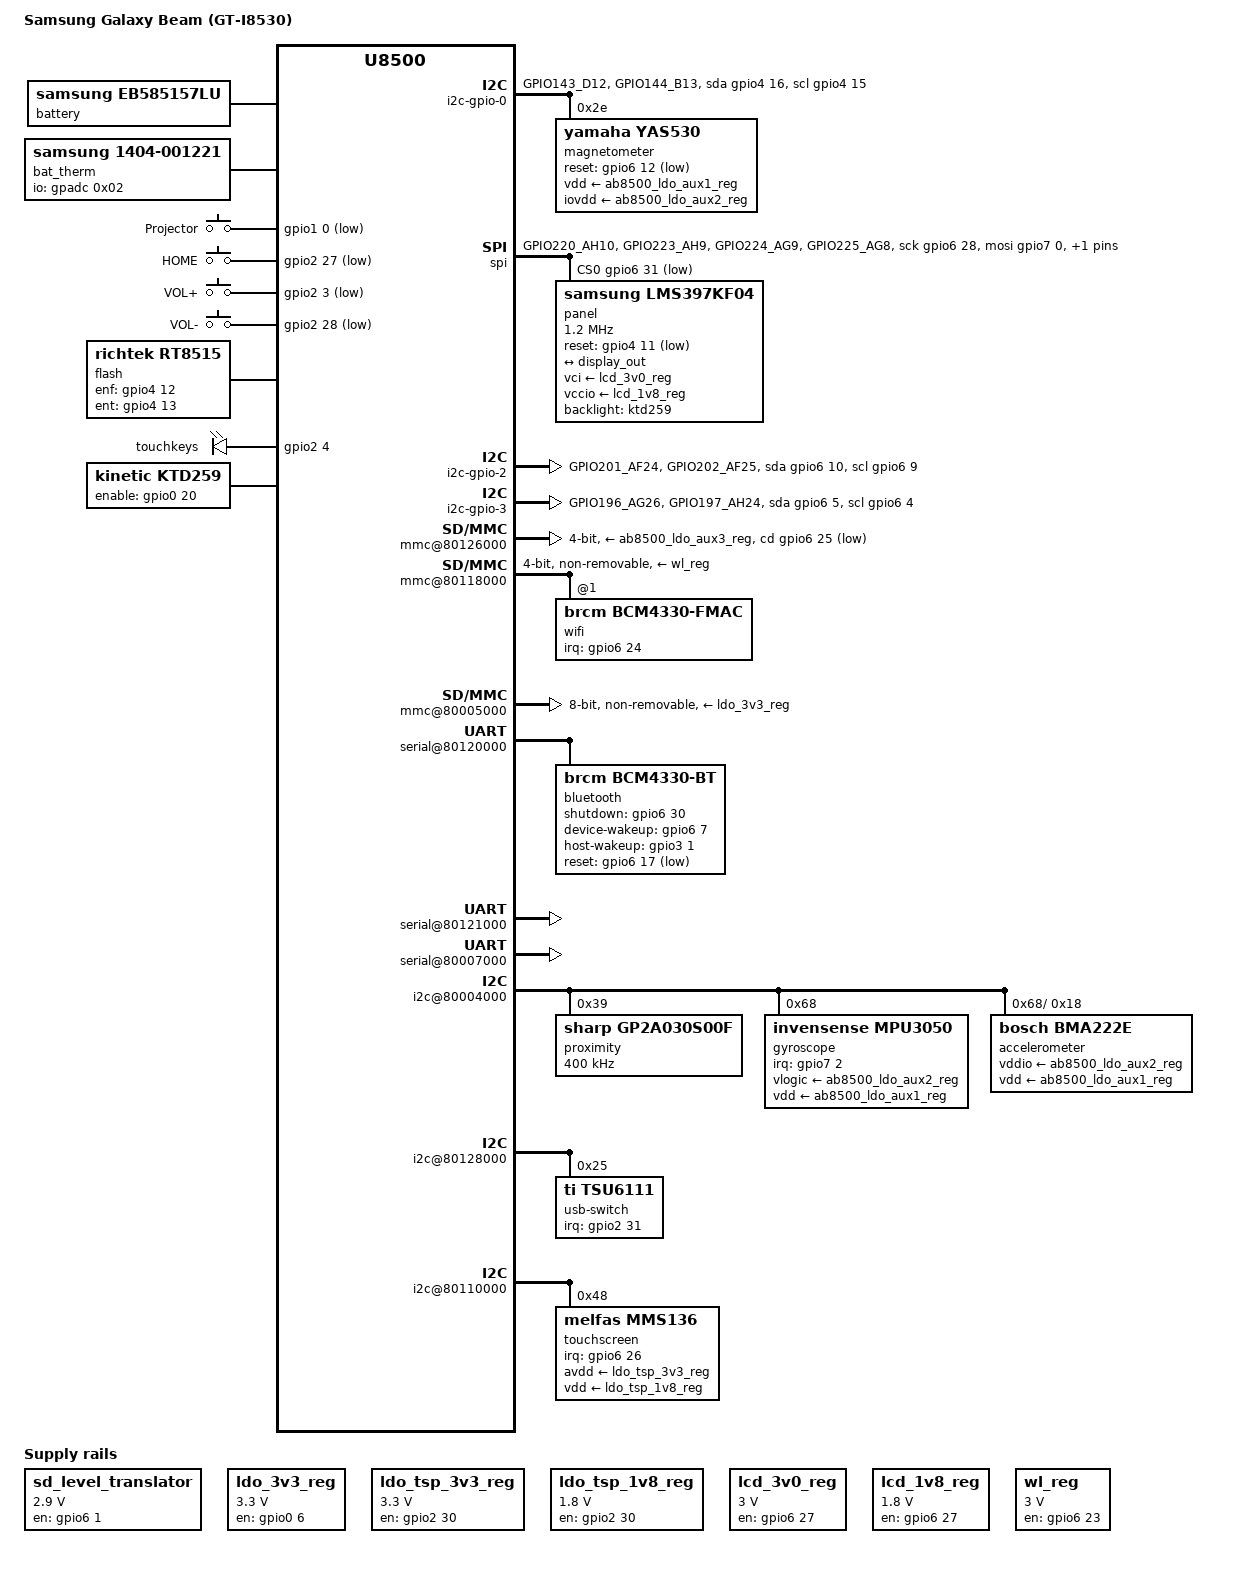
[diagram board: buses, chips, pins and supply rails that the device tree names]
/dts-v1/;
#include "ste-db8500.dtsi"
#include "ste-ab8500.dtsi"
#include "ste-dbx5x0-pinctrl.dtsi"
#include <dt-bindings/gpio/gpio.h>
#include <dt-bindings/leds/common.h>
#include <dt-bindings/input/input.h>
#include <dt-bindings/interrupt-controller/irq.h>
/ {
	model = "Samsung Galaxy Beam (GT-I8530)";
	compatible = "samsung,gavini", "st-ericsson,u8500";
	chosen {
		stdout-path = &serial2;
	};
	battery: battery {
		compatible = "samsung,eb585157lu";
	};
	thermal-zones {
		battery-thermal {
			polling-delay = <0>;
			polling-delay-passive = <0>;
			thermal-sensors = <&bat_therm>;
			trips {
				battery-crit-hi {
					temperature = <70000>;
					hysteresis = <2000>;
					type = "critical";
				};
			};
		};
	};
	bat_therm: thermistor {
		compatible = "samsung,1404-001221";
		io-channels = <&gpadc 0x02>;  
		pullup-uv = <1800000>;
		pullup-ohm = <230000>;
		pulldown-ohm = <0>;
		#thermal-sensor-cells = <0>;
	};
	sd_level_translator: regulator-gpio {
		compatible = "regulator-fixed";
		gpios = <&gpio6 1 GPIO_ACTIVE_HIGH>;
		enable-active-high;
		regulator-name = "sd-level-translator";
		regulator-min-microvolt = <2900000>;
		regulator-max-microvolt = <2900000>;
		regulator-type = "voltage";
		startup-delay-us = <200>;
		pinctrl-names = "default";
		pinctrl-0 = <&sd_level_translator_default>;
	};
	ldo_3v3_reg: regulator-gpio-ldo-3v3 {
		compatible = "regulator-fixed";
		regulator-name = "VMEM_3V3";
		regulator-min-microvolt = <3300000>;
		regulator-max-microvolt = <3300000>;
		gpio = <&gpio0 6 GPIO_ACTIVE_HIGH>;
		startup-delay-us = <5000>;  
		enable-active-high;
		pinctrl-names = "default";
		pinctrl-0 = <&emmc_ldo_en_default_mode>;
	};
	ldo_tsp_3v3_reg: regulator-gpio-tsp-ldo-3v3 {
		compatible = "regulator-fixed";
		regulator-name = "LDO_TSP_A3V3";
		regulator-min-microvolt = <3300000>;
		regulator-max-microvolt = <3300000>;
		gpio = <&gpio2 30 GPIO_ACTIVE_HIGH>;
		startup-delay-us = <70000>;
		enable-active-high;
		pinctrl-names = "default";
		pinctrl-0 = <&tsp_ldo_en_default_mode>;
	};
	ldo_tsp_1v8_reg: regulator-gpio-tsp-ldo-1v8 {
		compatible = "regulator-fixed";
		regulator-name = "VREG_TSP_1V8";
		regulator-min-microvolt = <1800000>;
		regulator-max-microvolt = <1800000>;
		gpio = <&gpio2 30 GPIO_ACTIVE_HIGH>;
		startup-delay-us = <70000>;
		enable-active-high;
		pinctrl-names = "default";
		pinctrl-0 = <&tsp_ldo_en_default_mode>;
	};
	lcd_3v0_reg: regulator-gpio-lcd-3v0 {
		compatible = "regulator-fixed";
		regulator-name = "VREG_LCD_3V0";
		regulator-min-microvolt = <3000000>;
		regulator-max-microvolt = <3000000>;
		gpio = <&gpio6 27 GPIO_ACTIVE_HIGH>;
		enable-active-high;
		pinctrl-names = "default";
		pinctrl-0 = <&lcd_pwr_en_default_mode>;
	};
	lcd_1v8_reg: regulator-gpio-lcd-1v8 {
		compatible = "regulator-fixed";
		regulator-name = "VREG_LCD_1V8";
		regulator-min-microvolt = <1800000>;
		regulator-max-microvolt = <1800000>;
		gpio = <&gpio6 27 GPIO_ACTIVE_HIGH>;
		enable-active-high;
		pinctrl-names = "default";
		pinctrl-0 = <&lcd_pwr_en_default_mode>;
	};
	wl_reg: regulator-gpio-wlan {
		compatible = "regulator-fixed";
		regulator-name = "WL_REG_ON";
		regulator-min-microvolt = <3000000>;
		regulator-max-microvolt = <3000000>;
		startup-delay-us = <100000>;
		gpio = <&gpio6 23 GPIO_ACTIVE_HIGH>;
		enable-active-high;
		pinctrl-names = "default";
		pinctrl-0 = <&wlan_ldo_en_default>;
	};
	gpio-keys {
		compatible = "gpio-keys";
		pinctrl-names = "default";
		pinctrl-0 = <&gpio_keys_default_mode>;
		button-projector {
			linux,code = <KEY_SWITCHVIDEOMODE>;
			label = "Projector";
			gpios = <&gpio1 0 GPIO_ACTIVE_LOW>;
		};
		button-home {
			linux,code = <KEY_HOME>;
			label = "HOME";
			gpios = <&gpio2 27 GPIO_ACTIVE_LOW>;
		};
		button-volup {
			linux,code = <KEY_VOLUMEUP>;
			label = "VOL+";
			gpios = <&gpio2 3 GPIO_ACTIVE_LOW>;
		};
		button-voldown {
			linux,code = <KEY_VOLUMEDOWN>;
			label = "VOL-";
			gpios = <&gpio2 28 GPIO_ACTIVE_LOW>;
		};
	};
	flash {
		compatible = "richtek,rt8515";
		enf-gpios = <&gpio4 12 GPIO_ACTIVE_HIGH>;
		ent-gpios = <&gpio4 13 GPIO_ACTIVE_HIGH>;
		richtek,rfs-ohms = <16000>;
		richtek,rts-ohms = <100000>;
		pinctrl-names = "default";
		pinctrl-0 = <&gpio_flash_default_mode>;
		led {
			function = LED_FUNCTION_FLASH;
			color = <LED_COLOR_ID_WHITE>;
			flash-max-timeout-us = <250000>;
			flash-max-microamp = <343750>;
			led-max-microamp = <55000>;
		};
	};
	gpio-leds {
		compatible = "gpio-leds";
		pinctrl-names = "default";
		pinctrl-0 = <&gpio_leds_default_mode>;
		used-led {
			label = "touchkeys";
			gpios = <&gpio2 4 GPIO_ACTIVE_HIGH>;
			default-state = "on";
		};
	};
	ktd259: backlight {
		compatible = "kinetic,ktd259";
		enable-gpios = <&gpio0 20 GPIO_ACTIVE_HIGH>;
		default-brightness = <13>;
		pinctrl-names = "default";
		pinctrl-0 = <&ktd259_backlight_default_mode>;
	};
	i2c-gpio-0 {
		compatible = "i2c-gpio";
		sda-gpios = <&gpio4 16 (GPIO_ACTIVE_HIGH|GPIO_OPEN_DRAIN)>;
		scl-gpios = <&gpio4 15 (GPIO_ACTIVE_HIGH|GPIO_OPEN_DRAIN)>;
		pinctrl-names = "default";
		pinctrl-0 = <&i2c_gpio_0_default>;
		#address-cells = <1>;
		#size-cells = <0>;
		magnetometer@2e {
			compatible = "yamaha,yas530";
			reg = <0x2e>;
			vdd-supply = <&ab8500_ldo_aux1_reg>;
			iovdd-supply = <&ab8500_ldo_aux2_reg>;
			reset-gpios = <&gpio6 12 GPIO_ACTIVE_LOW>;
			pinctrl-names = "default";
			pinctrl-0 = <&yas530_default>;
		};
	};
	spi {
		compatible = "spi-gpio";
		sck-gpios = <&gpio6 28 GPIO_ACTIVE_HIGH>;
		mosi-gpios = <&gpio7 0 GPIO_ACTIVE_HIGH>;
		miso-gpios = <&gpio7 1 GPIO_ACTIVE_HIGH>;
		cs-gpios = <&gpio6 31 GPIO_ACTIVE_LOW>;
		num-chipselects = <1>;
		pinctrl-names = "default";
		pinctrl-0 = <&spi_gpio_0_default>;
		#address-cells = <1>;
		#size-cells = <0>;
		panel@0 {
			compatible = "samsung,lms397kf04";
			spi-max-frequency = <1200000>;
			spi-cpha;
			spi-cpol;
			reg = <0>;
			vci-supply = <&lcd_3v0_reg>;
			vccio-supply = <&lcd_1v8_reg>;
			reset-gpios = <&gpio4 11 GPIO_ACTIVE_LOW>;
			pinctrl-names = "default";
			pinctrl-0 = <&panel_default_mode>;
			backlight = <&ktd259>;
			port {
				panel_in: endpoint {
					remote-endpoint = <&display_out>;
				};
			};
		};
	};
	i2c-gpio-2 {
		compatible = "i2c-gpio";
		sda-gpios = <&gpio6 10 (GPIO_ACTIVE_HIGH|GPIO_OPEN_DRAIN)>;
		scl-gpios = <&gpio6 9 (GPIO_ACTIVE_HIGH|GPIO_OPEN_DRAIN)>;
		pinctrl-names = "default";
		pinctrl-0 = <&i2c_gpio_2_default>;
		#address-cells = <1>;
		#size-cells = <0>;
	};
	i2c-gpio-3 {
		compatible = "i2c-gpio";
		sda-gpios = <&gpio6 5 (GPIO_ACTIVE_HIGH|GPIO_OPEN_DRAIN)>;
		scl-gpios = <&gpio6 4 (GPIO_ACTIVE_HIGH|GPIO_OPEN_DRAIN)>;
		pinctrl-names = "default";
		pinctrl-0 = <&i2c_gpio_3_default>;
		#address-cells = <1>;
		#size-cells = <0>;
	};
	soc {
		mmc@80126000 {
			arm,primecell-periphid = <0x10480180>;
			max-frequency = <50000000>;
			bus-width = <4>;
			cap-sd-highspeed;
			cap-mmc-highspeed;
			st,sig-pin-fbclk;
			full-pwr-cycle;
			vmmc-supply = <&ab8500_ldo_aux3_reg>;
			vqmmc-supply = <&sd_level_translator>;
			pinctrl-names = "default", "sleep";
			pinctrl-0 = <&mc0_a_2_default>;
			pinctrl-1 = <&mc0_a_2_sleep>;
			cd-gpios  = <&gpio6 25 GPIO_ACTIVE_LOW>;
			status = "okay";
		};
		mmc@80118000 {
			arm,primecell-periphid = <0x10480180>;
			max-frequency = <50000000>;
			bus-width = <4>;
			non-removable;
			cap-sd-highspeed;
			pinctrl-names = "default", "sleep";
			pinctrl-0 = <&mc1_a_2_default>;
			pinctrl-1 = <&mc1_a_2_sleep>;
			vmmc-supply = <&wl_reg>;
			#address-cells = <1>;
			#size-cells = <0>;
			status = "okay";
			wifi@1 {
				compatible = "brcm,bcm4330-fmac", "brcm,bcm4329-fmac";
				reg = <1>;
				interrupt-parent = <&gpio6>;
				interrupts = <24 IRQ_TYPE_EDGE_FALLING>;
				interrupt-names = "host-wake";
				pinctrl-names = "default";
				pinctrl-0 = <&wlan_default_mode>;
			};
		};
		mmc@80005000 {
			arm,primecell-periphid = <0x10480180>;
		        max-frequency = <50000000>;
			bus-width = <8>;
			non-removable;
			cap-mmc-highspeed;
			mmc-ddr-1_8v;
			no-sdio;
			no-sd;
			vmmc-supply = <&ldo_3v3_reg>;
			pinctrl-names = "default", "sleep";
			pinctrl-0 = <&mc2_a_1_default>;
			pinctrl-1 = <&mc2_a_1_sleep>;
			status = "okay";
		};
		serial@80120000 {
			pinctrl-names = "default", "sleep";
			pinctrl-0 = <&u0_a_1_default>;
			pinctrl-1 = <&u0_a_1_sleep>;
			status = "okay";
			bluetooth {
				compatible = "brcm,bcm4330-bt";
				shutdown-gpios = <&gpio6 30 GPIO_ACTIVE_HIGH>;
				device-wakeup-gpios = <&gpio6 7 GPIO_ACTIVE_HIGH>;
				host-wakeup-gpios = <&gpio3 1 GPIO_ACTIVE_HIGH>;
				reset-gpios = <&gpio6 17 GPIO_ACTIVE_LOW>;
				pinctrl-names = "default";
				pinctrl-0 = <&bluetooth_default_mode>;
			};
		};
		serial@80121000 {
			status = "okay";
			pinctrl-names = "default", "sleep";
			pinctrl-0 = <&u1rxtx_a_1_default>;
			pinctrl-1 = <&u1rxtx_a_1_sleep>;
		};
		serial@80007000 {
			status = "okay";
			pinctrl-names = "default", "sleep";
			pinctrl-0 = <&u2rxtx_c_1_default>;
			pinctrl-1 = <&u2rxtx_c_1_sleep>;
		};
		prcmu@80157000 {
			ab8500 {
				phy {
					pinctrl-names = "default", "sleep";
					pinctrl-0 = <&usb_a_1_default>;
					pinctrl-1 = <&usb_a_1_sleep>;
				};
				ab8500_fg {
					line-impedance-micro-ohms = <43000>;
				};
				regulator {
					ab8500_ldo_aux1 {
						regulator-name = "V-SENSORS-VDD";
						regulator-min-microvolt = <3000000>;
						regulator-max-microvolt = <3000000>;
					};
					ab8500_ldo_aux2 {
						regulator-name = "V-SENSORS-VIO";
						regulator-min-microvolt = <1800000>;
						regulator-max-microvolt = <1800000>;
					};
					ab8500_ldo_aux3 {
						regulator-name = "V-MMC-SD";
						regulator-min-microvolt = <1200000>;
						regulator-max-microvolt = <2910000>;
					};
				};
			};
		};
		i2c@80004000 {
			status = "okay";
			pinctrl-names = "default", "sleep";
			pinctrl-0 = <&i2c0_a_1_default>;
			pinctrl-1 = <&i2c0_a_1_sleep>;
			proximity@39 {
				compatible = "sharp,gp2a030s00f";
				clock-frequency = <400000>;
				reg = <0x39>;
			};
			gyroscope@68 {
				compatible = "invensense,mpu3050";
				reg = <0x68>;
				interrupt-parent = <&gpio7>;
				interrupts = <2 IRQ_TYPE_EDGE_FALLING>;
				mount-matrix = "0", "1", "0",
					       "1", "0", "0",
					       "0", "0", "1";
				vlogic-supply = <&ab8500_ldo_aux2_reg>;  
				vdd-supply = <&ab8500_ldo_aux1_reg>;  
				pinctrl-names = "default";
				pinctrl-0 = <&mpu3050_default>;
				i2c-gate {
					#address-cells = <1>;
					#size-cells = <0>;
					accelerometer@18 {
						compatible = "bosch,bma222e";
						reg = <0x18>;
						mount-matrix = "0", "-1", "0",
							       "1", "0", "0",
							       "0", "0", "1";
						vddio-supply = <&ab8500_ldo_aux2_reg>;  
						vdd-supply = <&ab8500_ldo_aux1_reg>;  
					};
				};
			};
		};
		i2c@80128000 {
			status = "okay";
			pinctrl-names = "default", "sleep";
			pinctrl-0 = <&i2c2_b_1_default>;
			pinctrl-1 = <&i2c2_b_1_sleep>;
			usb-switch@25 {
				compatible = "ti,tsu6111";
				reg = <0x25>;
				interrupt-parent = <&gpio2>;
				interrupts = <31 IRQ_TYPE_EDGE_FALLING>;
				pinctrl-names = "default";
				pinctrl-0 = <&tsu6111_default>;
			};
		};
		i2c@80110000 {
			status = "okay";
			pinctrl-names = "default", "sleep";
			pinctrl-0 = <&i2c3_c_2_default>;
			pinctrl-1 = <&i2c3_c_2_sleep>;
			touchscreen@48 {
				compatible = "melfas,mms136";
				reg = <0x48>;
				interrupt-parent = <&gpio6>;
				interrupts = <26 IRQ_TYPE_EDGE_FALLING>;
				avdd-supply = <&ldo_tsp_3v3_reg>;
				vdd-supply = <&ldo_tsp_1v8_reg>;
				pinctrl-names = "default";
				pinctrl-0 = <&tsp_default>;
				touchscreen-size-x = <480>;
				touchscreen-size-y = <800>;
			};
		};
		mcde@a0350000 {
			status = "okay";
			pinctrl-names = "default";
			pinctrl-0 = <&dpi_default_mode>;
			port {
				display_out: endpoint {
					remote-endpoint = <&panel_in>;
				};
			};
		};
	};
};
&pinctrl {
	sdi0 {
		mc0_a_2_default {
			default_cfg4 {
				pins = "GPIO217_AH12";  
				ste,config = <&gpio_in_nopull>;
			};
		};
	};
	mcde {
		dpi_default_mode: dpi_default {
			default_mux1 {
				function = "lcd";
				groups =
					"lcd_d0_d7_a_1",
					"lcd_d8_d11_a_1",
					"lcd_d12_d15_a_1",
					"lcd_d16_d23_b_1";
			};
			default_mux2 {
				function = "lcda";
				groups = "lcdaclk_b_1", "lcda_b_1";
			};
			default_cfg1 {
				pins = "GPIO150_C14", "GPIO169_D22", "GPIO170_C23", "GPIO171_D23";
				ste,config = <&in_nopull>;
			};
		};
	};
	panel {
		panel_default_mode: panel_default {
			gavini_cfg1 {
				pins = "GPIO139_C9";
				ste,config = <&gpio_out_lo>;
			};
		};
	};
	emmc-ldo {
		emmc_ldo_en_default_mode: emmc_ldo_default {
			gavini_cfg1 {
				pins = "GPIO6_AF6";
				ste,config = <&gpio_out_hi>;
			};
		};
	};
	tsp-ldo {
		tsp_ldo_en_default_mode: tsp_ldo_default {
			gavini_cfg1 {
				pins = "GPIO94_D7";
				ste,config = <&gpio_out_hi>;
			};
		};
	};
	yas530 {
		yas530_default: yas530_janice {
			janice_cfg1 {
				pins = "GPIO204_AF23";
				ste,config = <&gpio_out_hi>;
			};
		};
	};
	flash {
		gpio_flash_default_mode: flash_default {
			janice_cfg1 {
				pins = "GPIO140_B11", "GPIO141_C12";
				ste,config = <&gpio_out_lo>;
			};
		};
	};
	gpio-leds {
		gpio_leds_default_mode: gpio_leds_default {
			gavini_cfg1 {
				pins = "GPIO68_E1";
				ste,config = <&gpio_out_hi>;
			};
		};
	};
	backlight {
		ktd259_backlight_default_mode: backlight_default {
			skomer_cfg1 {
				pins = "GPIO20_AB4";  
				ste,config = <&gpio_out_lo>;
			};
		};
	};
	touchkey-ldo {
		tsp_ldo_on2_default_mode: tsp_ldo_on2_default {
			gavini_cfg1 {
				pins = "GPIO89_E6";
				ste,config = <&gpio_out_lo>;
			};
		};
	};
	touchkey {
		touchkey_default_mode: touchkey_default {
			gavini_cfg1 {
				pins = "GPIO198_AG25";
				ste,config = <&gpio_in_nopull>;
			};
			gavini_cfg2 {
				pins = "GPIO205_AG23";
				ste,config = <&gpio_in_pd>;
			};
		};
	};
	lcd-ldo {
		lcd_pwr_en_default_mode: lcd_pwr_en_default {
			gavini_cfg1 {
				pins = "GPIO219_AG10";
				ste,config = <&gpio_out_hi>;
			};
		};
	};
	wlan-ldo {
		wlan_ldo_en_default: wlan_ldo_default {
			gavini_cfg1 {
				pins = "GPIO215_AH13";
				ste,config = <&gpio_out_lo>;
			};
		};
	};
	sd-level-translator {
		sd_level_translator_default: sd_level_translator_default {
			skomer_cfg1 {
				pins = "GPIO193_AH27";
				ste,config = <&gpio_out_hi>;
			};
		};
	};
	gpio-keys {
		gpio_keys_default_mode: gpio_keys_default {
			skomer_cfg1 {
				pins = "GPIO32_V2",  
				       "GPIO67_G2",  
				       "GPIO91_B6",  
				       "GPIO92_D6";  
				ste,config = <&gpio_in_pu>;
			};
		};
	};
	tsp {
		tsp_default: tsp_default {
			gavini_cfg1 {
				pins = "GPIO218_AH11";	 
				ste,config = <&gpio_in_nopull>;
			};
		};
	};
	mpu3050 {
		mpu3050_default: mpu3050 {
			gavini_cfg1 {
				pins = "GPIO226_AF8";
				ste,config = <&gpio_in_nopull>;
			};
		};
	};
	i2c-gpio-0 {
		i2c_gpio_0_default: i2c_gpio_0 {
			gavini_cfg1 {
				pins = "GPIO143_D12", "GPIO144_B13";
				ste,config = <&gpio_in_nopull>;
			};
		};
	};
	i2c-gpio-2 {
		i2c_gpio_2_default: i2c_gpio_2 {
			gavini_cfg1 {
				pins = "GPIO201_AF24", "GPIO202_AF25";
				ste,config = <&gpio_in_nopull>;
			};
		};
	};
	i2c-gpio-3 {
		i2c_gpio_3_default: i2c_gpio_3 {
			gavini_cfg1 {
				pins = "GPIO196_AG26", "GPIO197_AH24";
				ste,config = <&gpio_in_nopull>;
			};
		};
	};
	spi-gpio-0 {
		spi_gpio_0_default: spi_gpio_0_d {
			gavini_cfg1 {
				pins = "GPIO220_AH10", "GPIO223_AH9", "GPIO224_AG9";
				ste,config = <&gpio_out_hi>;
			};
			gavini_cfg2 {
				pins = "GPIO225_AG8";
				ste,config = <&gpio_in_nopull>;
			};
		};
		spi_gpio_0_sleep: spi_gpio_0_s {
			gavini_cfg1 {
				pins = "GPIO220_AH10", "GPIO223_AH9",
				     "GPIO224_AG9", "GPIO225_AG8";
				ste,config = <&gpio_out_hi>;
			};
			gavini_cfg2 {
				pins = "GPIO225_AG8";
				ste,config = <&gpio_out_lo>;
			};
		};
	};
	wlan {
		wlan_default_mode: wlan_default {
			gavini_cfg2 {
				pins = "GPIO216_AG12";
				ste,config = <&gpio_in_pd>;
			};
		};
	};
	bluetooth {
		bluetooth_default_mode: bluetooth_default {
			gavini_cfg1 {
				pins = "GPIO199_AH23", "GPIO222_AJ9";
				ste,config = <&gpio_out_lo>;
			};
			gavini_cfg2 {
				pins = "GPIO97_D9";
				ste,config = <&gpio_in_nopull>;
			};
			gavini_cfg3 {
				pins = "GPIO209_AG15";
				ste,config = <&gpio_out_hi>;
			};
		};
	};
	tsu6111 {
		tsu6111_default: tsu6111 {
			gavini_cfg1 {
				pins = "GPIO95_E8";
				ste,config = <&gpio_in_nopull>;
			};
		};
	};
};
